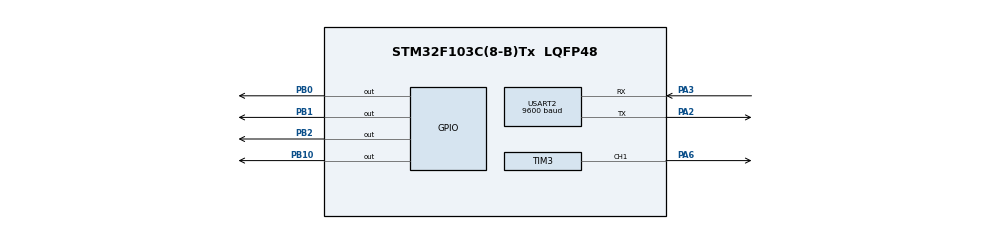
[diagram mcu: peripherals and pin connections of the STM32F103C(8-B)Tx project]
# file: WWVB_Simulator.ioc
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Mcu.Family=STM32F1
Mcu.Name=STM32F103C(8-B)Tx
Mcu.Package=LQFP48
NVIC.PriorityGroup=NVIC_PRIORITYGROUP_4
NVIC.RTC_IRQn=true\:0\:0\:false\:false\:true\:true\:true\:true
NVIC.TIM2_IRQn=true\:0\:0\:false\:false\:true\:true\:true\:true
NVIC.USART2_IRQn=true\:0\:0\:false\:false\:true\:true\:true\:true
PA13.Mode=Serial_Wire
PA13.Signal=SYS_JTMS-SWDIO
PA14.Mode=Serial_Wire
PA14.Signal=SYS_JTCK-SWCLK
PA2.Mode=Asynchronous
PA2.Signal=USART2_TX
PA3.Mode=Asynchronous
PA3.Signal=USART2_RX
PA6.Signal=S_TIM3_CH1
PB0.Signal=GPIO_Output
PB1.Signal=GPIO_Output
PB10.Signal=GPIO_Output
PB2.Signal=GPIO_Output
PC14-OSC32_IN.Mode=LSE-External-Oscillator
PC14-OSC32_IN.Signal=RCC_OSC32_IN
PC15-OSC32_OUT.Mode=LSE-External-Oscillator
PC15-OSC32_OUT.Signal=RCC_OSC32_OUT
PD0-OSC_IN.Mode=HSE-External-Oscillator
PD0-OSC_IN.Signal=RCC_OSC_IN
PD1-OSC_OUT.Mode=HSE-External-Oscillator
PD1-OSC_OUT.Signal=RCC_OSC_OUT
ProjectManager.HeapSize=0x200
ProjectManager.StackSize=0x400
ProjectManager.TargetToolchain=STM32CubeIDE
RCC.APB1Freq_Value=8000000
RCC.APB2Freq_Value=8000000
RCC.RTCClockSelection=RCC_RTCCLKSOURCE_LSE
RCC.SYSCLKSource=RCC_SYSCLKSOURCE_HSE
RTC.Format=RTC_FORMAT_BIN
RTC.OutPut=RTC_OUTPUTSOURCE_ALARM
SH.S_TIM3_CH1.0=TIM3_CH1,PWM Generation1 CH1
TIM2.Period=1000-1
TIM2.Prescaler=800-1
TIM3.AutoReloadPreload=TIM_AUTORELOAD_PRELOAD_DISABLE
TIM3.Channel-PWM\ Generation1\ CH1=TIM_CHANNEL_1
TIM3.Period=133-1
TIM3.Prescaler=0
TIM3.Pulse-PWM\ Generation1\ CH1=132
USART2.BaudRate=9600
USART2.VirtualMode=VM_ASYNC
VP_RTC_VS_RTC_Activate.Mode=RTC_Enabled
VP_TIM2_VS_ClockSourceINT.Mode=Internal
board=custom

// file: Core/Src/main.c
/* USER CODE BEGIN Header */
/**
  ******************************************************************************
  * @file           : main.c
  * @brief          : Main program body
  ******************************************************************************
  * @attention
  *
  * Copyright (c) 2023 STMicroelectronics.
  * All rights reserved.
  *
  * This software is licensed under terms that can be found in the LICENSE file
  * in the root directory of this software component.
  * If no LICENSE file comes with this software, it is provided AS-IS.
  *
  ******************************************************************************
  */
/* USER CODE END Header */
#include "main.h"

/* USER CODE BEGIN Includes */
#include "UnixTimeWWVB.h"
/* USER CODE END Includes */

RTC_HandleTypeDef hrtc;

TIM_HandleTypeDef htim2;
TIM_HandleTypeDef htim3;

UART_HandleTypeDef huart2;

void SystemClock_Config(void);
static void MX_GPIO_Init(void);
static void MX_TIM3_Init(void);
static void MX_RTC_Init(void);
static void MX_USART2_UART_Init(void);
static void MX_TIM2_Init(void);

int main(void)
{

  /* MCU Configuration--------------------------------------------------------*/

  /* Reset of all peripherals, Initializes the Flash interface and the Systick. */
  HAL_Init();

  /* Configure the system clock */
  SystemClock_Config();

  /* Initialize all configured peripherals */
  MX_GPIO_Init();
  MX_TIM3_Init();
  MX_RTC_Init();
  MX_USART2_UART_Init();
  MX_TIM2_Init();
  /* USER CODE BEGIN 2 */
  UnixTimeWWVB::InitWWVB(&hrtc, &htim2, &htim3, &huart2);
  /* USER CODE END 2 */

  /* Infinite loop */
  while (1)
  {

  }
}

void SystemClock_Config(void)
{
  RCC_OscInitTypeDef RCC_OscInitStruct = {0};
  RCC_ClkInitTypeDef RCC_ClkInitStruct = {0};
  RCC_PeriphCLKInitTypeDef PeriphClkInit = {0};

  /** Initializes the RCC Oscillators according to the specified parameters
  * in the RCC_OscInitTypeDef structure.
  */
  RCC_OscInitStruct.OscillatorType = RCC_OSCILLATORTYPE_HSE|RCC_OSCILLATORTYPE_LSE;
  RCC_OscInitStruct.HSEState = RCC_HSE_ON;
  RCC_OscInitStruct.LSEState = RCC_LSE_ON;
  RCC_OscInitStruct.PLL.PLLState = RCC_PLL_NONE;
  if (HAL_RCC_OscConfig(&RCC_OscInitStruct) != HAL_OK)
  {
    Error_Handler();
  }

  /** Initializes the CPU, AHB and APB buses clocks
  */
  RCC_ClkInitStruct.ClockType = RCC_CLOCKTYPE_HCLK|RCC_CLOCKTYPE_SYSCLK
                              |RCC_CLOCKTYPE_PCLK1|RCC_CLOCKTYPE_PCLK2;
  RCC_ClkInitStruct.SYSCLKSource = RCC_SYSCLKSOURCE_HSE;
  RCC_ClkInitStruct.AHBCLKDivider = RCC_SYSCLK_DIV1;
  RCC_ClkInitStruct.APB1CLKDivider = RCC_HCLK_DIV1;
  RCC_ClkInitStruct.APB2CLKDivider = RCC_HCLK_DIV1;

  if (HAL_RCC_ClockConfig(&RCC_ClkInitStruct, FLASH_LATENCY_0) != HAL_OK)
  {
    Error_Handler();
  }
  PeriphClkInit.PeriphClockSelection = RCC_PERIPHCLK_RTC;
  PeriphClkInit.RTCClockSelection = RCC_RTCCLKSOURCE_LSE;
  if (HAL_RCCEx_PeriphCLKConfig(&PeriphClkInit) != HAL_OK)
  {
    Error_Handler();
  }
}

static void MX_RTC_Init(void)
{

  /** Initialize RTC Only
  */
  hrtc.Instance = RTC;
  hrtc.Init.AsynchPrediv = RTC_AUTO_1_SECOND;
  hrtc.Init.OutPut = RTC_OUTPUTSOURCE_ALARM;
  if (HAL_RTC_Init(&hrtc) != HAL_OK)
  {
    Error_Handler();
  }

}

static void MX_TIM2_Init(void)
{

  TIM_ClockConfigTypeDef sClockSourceConfig = {0};
  TIM_MasterConfigTypeDef sMasterConfig = {0};

  htim2.Instance = TIM2;
  htim2.Init.Prescaler = 800-1;
  htim2.Init.CounterMode = TIM_COUNTERMODE_UP;
  htim2.Init.Period = 1000-1;
  htim2.Init.ClockDivision = TIM_CLOCKDIVISION_DIV1;
  htim2.Init.AutoReloadPreload = TIM_AUTORELOAD_PRELOAD_DISABLE;
  if (HAL_TIM_Base_Init(&htim2) != HAL_OK)
  {
    Error_Handler();
  }
  sClockSourceConfig.ClockSource = TIM_CLOCKSOURCE_INTERNAL;
  if (HAL_TIM_ConfigClockSource(&htim2, &sClockSourceConfig) != HAL_OK)
  {
    Error_Handler();
  }
  sMasterConfig.MasterOutputTrigger = TIM_TRGO_RESET;
  sMasterConfig.MasterSlaveMode = TIM_MASTERSLAVEMODE_DISABLE;
  if (HAL_TIMEx_MasterConfigSynchronization(&htim2, &sMasterConfig) != HAL_OK)
  {
    Error_Handler();
  }

}

static void MX_TIM3_Init(void)
{

  TIM_MasterConfigTypeDef sMasterConfig = {0};
  TIM_OC_InitTypeDef sConfigOC = {0};

  htim3.Instance = TIM3;
  htim3.Init.Prescaler = 0;
  htim3.Init.CounterMode = TIM_COUNTERMODE_UP;
  htim3.Init.Period = 133-1;
  htim3.Init.ClockDivision = TIM_CLOCKDIVISION_DIV1;
  htim3.Init.AutoReloadPreload = TIM_AUTORELOAD_PRELOAD_DISABLE;
  if (HAL_TIM_PWM_Init(&htim3) != HAL_OK)
  {
    Error_Handler();
  }
  sMasterConfig.MasterOutputTrigger = TIM_TRGO_RESET;
  sMasterConfig.MasterSlaveMode = TIM_MASTERSLAVEMODE_DISABLE;
  if (HAL_TIMEx_MasterConfigSynchronization(&htim3, &sMasterConfig) != HAL_OK)
  {
    Error_Handler();
  }
  sConfigOC.OCMode = TIM_OCMODE_PWM1;
  sConfigOC.Pulse = 132;
  sConfigOC.OCPolarity = TIM_OCPOLARITY_HIGH;
  sConfigOC.OCFastMode = TIM_OCFAST_DISABLE;
  if (HAL_TIM_PWM_ConfigChannel(&htim3, &sConfigOC, TIM_CHANNEL_1) != HAL_OK)
  {
    Error_Handler();
  }
  HAL_TIM_MspPostInit(&htim3);

}

static void MX_USART2_UART_Init(void)
{

  huart2.Instance = USART2;
  huart2.Init.BaudRate = 9600;
  huart2.Init.WordLength = UART_WORDLENGTH_8B;
  huart2.Init.StopBits = UART_STOPBITS_1;
  huart2.Init.Parity = UART_PARITY_NONE;
  huart2.Init.Mode = UART_MODE_TX_RX;
  huart2.Init.HwFlowCtl = UART_HWCONTROL_NONE;
  huart2.Init.OverSampling = UART_OVERSAMPLING_16;
  if (HAL_UART_Init(&huart2) != HAL_OK)
  {
    Error_Handler();
  }

}

static void MX_GPIO_Init(void)
{
  GPIO_InitTypeDef GPIO_InitStruct = {0};

  /* GPIO Ports Clock Enable */
  __HAL_RCC_GPIOC_CLK_ENABLE();
  __HAL_RCC_GPIOD_CLK_ENABLE();
  __HAL_RCC_GPIOA_CLK_ENABLE();
  __HAL_RCC_GPIOB_CLK_ENABLE();

  /*Configure GPIO pin Output Level */
  HAL_GPIO_WritePin(GPIOB, GPIO_PIN_0|GPIO_PIN_1|GPIO_PIN_2|GPIO_PIN_10, GPIO_PIN_RESET);

  /*Configure GPIO pins : PB0 PB1 PB2 PB10 */
  GPIO_InitStruct.Pin = GPIO_PIN_0|GPIO_PIN_1|GPIO_PIN_2|GPIO_PIN_10;
  GPIO_InitStruct.Mode = GPIO_MODE_OUTPUT_PP;
  GPIO_InitStruct.Pull = GPIO_NOPULL;
  GPIO_InitStruct.Speed = GPIO_SPEED_FREQ_LOW;
  HAL_GPIO_Init(GPIOB, &GPIO_InitStruct);

}

void Error_Handler(void)
{
  __disable_irq();
  while (1)
  {
  }
}
